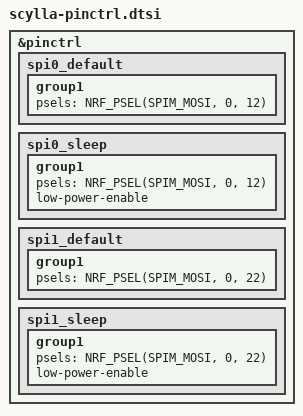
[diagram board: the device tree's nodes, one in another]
/*
 * Copyright (c) 2023 The ZMK Contributors
 * SPDX-License-Identifier: MIT
 */

&pinctrl {
    spi0_default: spi0_default {
        group1 {
            psels = <NRF_PSEL(SPIM_MOSI, 0, 12)>;
        };
    };

    spi0_sleep: spi0_sleep {
        group1 {
            psels = <NRF_PSEL(SPIM_MOSI, 0, 12)>;
            low-power-enable;
        };
    };

    spi1_default: spi1_default {
        group1 {
            psels = <NRF_PSEL(SPIM_MOSI, 0, 22)>;
        };
    };

    spi1_sleep: spi1_sleep {
        group1 {
            psels = <NRF_PSEL(SPIM_MOSI, 0, 22)>;
            low-power-enable;
        };
    };
};
